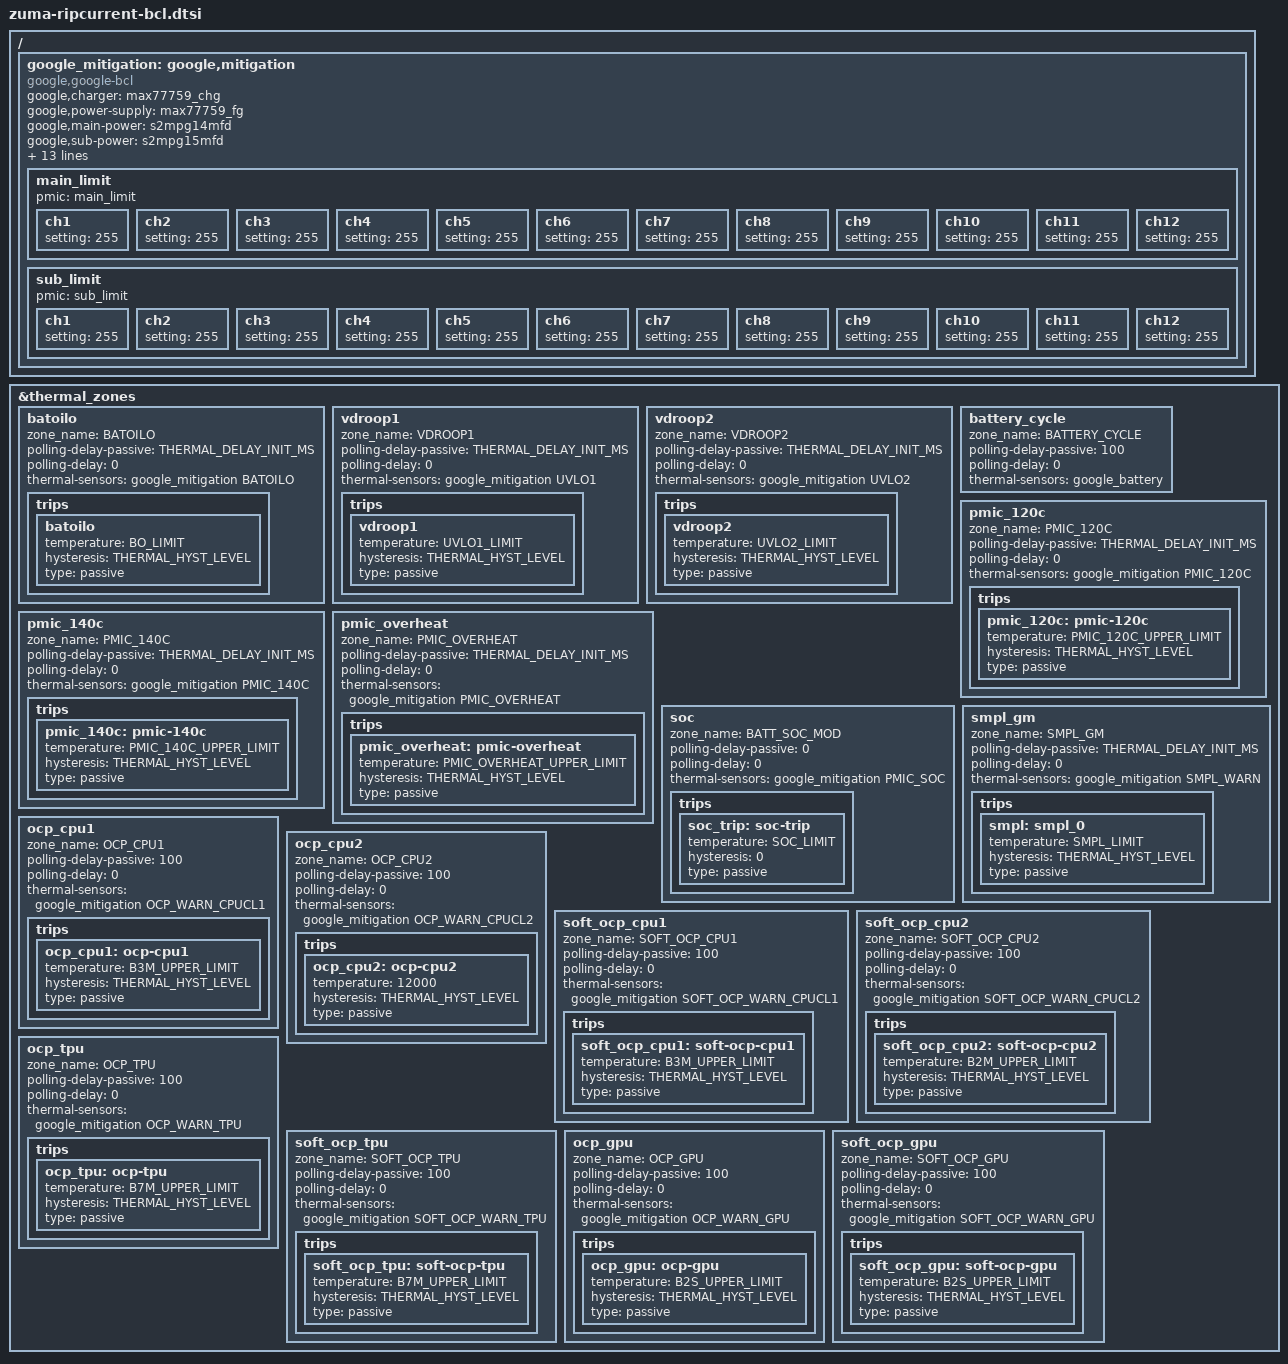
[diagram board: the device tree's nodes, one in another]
// SPDX-License-Identifier: GPL-2.0
/*
 * Google Zuma Ripcurrent-specific bcl device tree source
 *
 * Copyright (c) 2022 Google, LLC
 *		https://www.google.com
 */

#include <dt-bindings/thermal/thermal.h>
#include <dt-bindings/soc/google/zuma-bcl.h>

/ {
	fragment@battery {
		target-path = "/";
		__overlay__ {
			google_mitigation: google,mitigation {
				compatible = "google,google-bcl";
				#thermal-sensor-cells = <1>;
				google,charger = <&max77759_chg>;
				google,power-supply = <&max77759_fg>;
				google,main-power = <&s2mpg14mfd>;
				google,sub-power = <&s2mpg15mfd>;
				ppm_settings = <0>;
				mpmm_settings = <0x1a>;
				tpu_con_heavy = <0xfff041c3>;
				tpu_con_light = <0xfff041c1>;
				tpu_clkdivstep = <0x1>;
				gpu_con_heavy = <0xfff04385>;
				gpu_con_light = <0xfff041c1>;
				gpu_clkdivstep = <0x1>;
				cpu2_clkdivstep = <0x1>;
				cpu1_clkdivstep = <0x1>;
				cpu0_clkdivstep = <0x1>;
				odpm_ratio = <3>;
				gpios = <&gpa9 5 0>,		/* VDROOP1 */
					<&gpa9 6 0>,		/* VDROOP2 */
					<&gpp19 2 0>,		/* MODEM 1 */
					<&gpp10 0 0>;		/* MODEM 2 */

				main_limit {
					pmic = "main_limit";
					ch1 {
						/* BUCK1M Min: 0.006868132 mW Max: 14403.51 mW */
						setting = <255>;   /* BUCK1M LSB: 0.006868132 mW */
					};
					ch2 {
						/* BUCK2M Min: 0.013736264 mW Max: 28807.01 mW */
						setting = <255>;   /* BUCK2M LSB: 0.013736264 mW */
					};
					ch3 {
						/* BUCK3M Min: 0.020604396 mW Max: 43210.53 mW */
						setting = <255>;   /* BUCK3M LSB: 0.020604396 mW */
					};
					ch4 {
						/* BUCK4M Min: 0.013736264 mW Max: 28807.01 mW */
						setting = <255>;   /* BUCK4M LSB: 0.013736264 mW */
					};
					ch5 {
						/* BUCK5M Min: 0.020604396 mW Max: 43210.53 mW */
						setting = <255>;   /* BUCK5M LSB: 0.020604396 mW */
					};
					ch6 {
						/* BUCK6M Min: 0.006868132 mW Max: 14403.51 mW */
						setting = <255>;   /* BUCK6M LSB: 0.006868132 mW */
					};
					ch7 {
						/* BUCK7M Min: 0.020604396 mW Max: 43210.53 mW */
						setting = <255>;   /* BUCK7M LSB: 0.020604396 mW */
					};
					ch8 {
						/* BUCK8M Min: 0.006868132 mW Max: 14403.51 mW */
						setting = <255>;   /* BUCK8M LSB: 0.006868132 mW */
					};
					ch9 {
						setting = <255>;   /* LDO15M LSB: 0.001831502 mW */
					};
					ch10 {
						setting = <255>;   /* VSEN_C1 LSB: 0.0021978021 V */
					};
					ch11 {
						setting = <255>;  /* VSEN_C2 LSB: 0.0021978021 V */
					};
					ch12 {
						setting = <255>;  /* VSEN_C3 LSB: 0.0021978021 V */
					};
				};
				sub_limit {
					pmic = "sub_limit";
					ch1 {
						/* BUCK1S Min: 0.013736264 mW Max: 28807.01 mW */
						setting = <255>;   /* BUCK1S LSB: 0.013736264 mW */
					};
					ch2 {
						/* BUCK2S Min: 0.013736264 mW Max: 28807.01 mW */
						setting = <255>;   /* BUCK2S LSB: 0.013736264 mW */
					};
					ch3 {
						/* BUCK4S Min: 0.006868132 mW Max: 14403.51 mW */
						setting = <255>;   /* BUCK4S LSB: 0.006868132 mW */
					};
					ch4 {
						/* BUCK5S Min: 0.006868132 mW Max: 14403.51 mW */
						setting = <255>;   /* BUCK5S LSB: 0.006868132 mW */
					};
					ch5 {
						/* BUCK8S Min: 0.006868132 mW Max: 14403.51 mW */
						setting = <255>;   /* BUCK8S LSB: 0.006868132 mW */
					};
					ch6 {
						/* BUCK9S Min: 0.006868132 mW Max: 14403.51 mW */
						setting = <255>;   /* BUCK9S LSB: 0.006868132 mW */
					};
					ch7 {
						setting = <255>;   /* LDO2S LSB: 0.001831502 mW */
					};
					ch8 {
						setting = <255>;   /* LDO9S LSB: 0.000457875 mW */
					};
					ch9 {
						setting = <255>;   /* LDO29S LSB: 0.000915751 mW */
					};
					ch10 {
						setting = <255>;  /* VSEN_C4 LSB: 0.0021978021 V */
					};
					ch11 {
						setting = <255>;  /* VSEN_C5 LSB: 0.0021978021 V */
					};
					ch12 {
						setting = <255>;  /* VSEN_C6 LSB: 0.0021978021 V */
					};
				};
			};
		};
	};
};

/* Thermal Zones */
&thermal_zones {
	batoilo {
		zone_name  = "BATOILO";
		polling-delay-passive = <THERMAL_DELAY_INIT_MS>;
		polling-delay = <0>;
		thermal-sensors = <&google_mitigation BATOILO>;
		trips {
			batoilo: batoilo{
				temperature = <BO_LIMIT>;
				hysteresis = <THERMAL_HYST_LEVEL>;
				type = "passive";
			};
		};
	};

	vdroop1 {
		zone_name  = "VDROOP1";
		polling-delay-passive = <THERMAL_DELAY_INIT_MS>;
		polling-delay = <0>;
		thermal-sensors = <&google_mitigation UVLO1>;
		trips {
			vdroop1: vdroop1{
				temperature = <UVLO1_LIMIT>;
				hysteresis = <THERMAL_HYST_LEVEL>;
				type = "passive";
			};
		};
	};

	vdroop2 {
		zone_name  = "VDROOP2";
		polling-delay-passive = <THERMAL_DELAY_INIT_MS>;
		polling-delay = <0>;
		thermal-sensors = <&google_mitigation UVLO2>;
		trips {
			vdroop2: vdroop2{
				temperature = <UVLO2_LIMIT>;
				hysteresis = <THERMAL_HYST_LEVEL>;
				type = "passive";
			};
		};
	};

	battery_cycle {
		zone_name  = "BATTERY_CYCLE";
		polling-delay-passive = <100>;
		polling-delay = <0>;
		thermal-sensors = <&google_battery>;
	};

	pmic_120c {
		zone_name  = "PMIC_120C";
		polling-delay-passive = <THERMAL_DELAY_INIT_MS>;
		polling-delay = <0>;
		thermal-sensors = <&google_mitigation PMIC_120C>;
		trips {
			pmic_120c: pmic-120c {
				temperature = <PMIC_120C_UPPER_LIMIT>;
				hysteresis = <THERMAL_HYST_LEVEL>;
				type = "passive";
			};
		};
	};

	pmic_140c {
		zone_name  = "PMIC_140C";
		polling-delay-passive = <THERMAL_DELAY_INIT_MS>;
		polling-delay = <0>;
		thermal-sensors = <&google_mitigation PMIC_140C>;
		trips {
			pmic_140c: pmic-140c {
				temperature = <PMIC_140C_UPPER_LIMIT>;
				hysteresis = <THERMAL_HYST_LEVEL>;
				type = "passive";
			};
		};
	};

	pmic_overheat {
		zone_name  = "PMIC_OVERHEAT";
		polling-delay-passive = <THERMAL_DELAY_INIT_MS>;
		polling-delay = <0>;
		thermal-sensors = <&google_mitigation PMIC_OVERHEAT>;
		trips {
			pmic_overheat: pmic-overheat{
				temperature = <PMIC_OVERHEAT_UPPER_LIMIT>;
				hysteresis = <THERMAL_HYST_LEVEL>;
				type = "passive";
			};
		};
	};

	soc {
		zone_name  = "BATT_SOC_MOD";
		polling-delay-passive = <0>;
		polling-delay = <0>;
		thermal-sensors = <&google_mitigation PMIC_SOC>;

		trips {
			soc_trip:soc-trip {
				temperature = <SOC_LIMIT>;
				hysteresis = <0>;
				type = "passive";
			};
		};
	};

	smpl_gm {
		zone_name  = "SMPL_GM";
		polling-delay-passive = <THERMAL_DELAY_INIT_MS>;
		polling-delay = <0>;
		thermal-sensors = <&google_mitigation SMPL_WARN>;

		trips {
			smpl:smpl_0 {
				temperature = <SMPL_LIMIT>;
				hysteresis = <THERMAL_HYST_LEVEL>;
				type = "passive";
			};
		};
	};
	ocp_cpu1 {
		zone_name  = "OCP_CPU1";
		polling-delay-passive = <100>;
		polling-delay = <0>;
		thermal-sensors = <&google_mitigation OCP_WARN_CPUCL1>;

		trips {
			ocp_cpu1:ocp-cpu1 {
				temperature = <B3M_UPPER_LIMIT>;
				hysteresis = <THERMAL_HYST_LEVEL>;
				type = "passive";
			};
		};
	};
	ocp_cpu2 {
		zone_name  = "OCP_CPU2";
		polling-delay-passive = <100>;
		polling-delay = <0>;
		thermal-sensors = <&google_mitigation OCP_WARN_CPUCL2>;

		trips {
			ocp_cpu2:ocp-cpu2 {
				temperature = <12000>;
				hysteresis = <THERMAL_HYST_LEVEL>;
				type = "passive";
			};
		};
	};
	soft_ocp_cpu1 {
		zone_name  = "SOFT_OCP_CPU1";
		polling-delay-passive = <100>;
		polling-delay = <0>;
		thermal-sensors = <&google_mitigation SOFT_OCP_WARN_CPUCL1>;

		trips {
			soft_ocp_cpu1:soft-ocp-cpu1 {
				temperature = <B3M_UPPER_LIMIT>;
				hysteresis = <THERMAL_HYST_LEVEL>;
				type = "passive";
			};
		};
	};
	soft_ocp_cpu2 {
		zone_name  = "SOFT_OCP_CPU2";
		polling-delay-passive = <100>;
		polling-delay = <0>;
		thermal-sensors = <&google_mitigation SOFT_OCP_WARN_CPUCL2>;

		trips {
			soft_ocp_cpu2:soft-ocp-cpu2 {
				temperature = <B2M_UPPER_LIMIT>;
				hysteresis = <THERMAL_HYST_LEVEL>;
				type = "passive";
			};
		};
	};
	ocp_tpu {
		zone_name  = "OCP_TPU";
		polling-delay-passive = <100>;
		polling-delay = <0>;
		thermal-sensors = <&google_mitigation OCP_WARN_TPU>;

		trips {
			ocp_tpu:ocp-tpu{
				temperature = <B7M_UPPER_LIMIT>;
				hysteresis = <THERMAL_HYST_LEVEL>;
				type = "passive";
			};
		};
	};
	soft_ocp_tpu {
		zone_name  = "SOFT_OCP_TPU";
		polling-delay-passive = <100>;
		polling-delay = <0>;
		thermal-sensors = <&google_mitigation SOFT_OCP_WARN_TPU>;

		trips {
			soft_ocp_tpu:soft-ocp-tpu {
				temperature = <B7M_UPPER_LIMIT>;
				hysteresis = <THERMAL_HYST_LEVEL>;
				type = "passive";
			};
		};
	};
	ocp_gpu {
		zone_name  = "OCP_GPU";
		polling-delay-passive = <100>;
		polling-delay = <0>;
		thermal-sensors = <&google_mitigation OCP_WARN_GPU>;

		trips {
			ocp_gpu:ocp-gpu{
				temperature = <B2S_UPPER_LIMIT>;
				hysteresis = <THERMAL_HYST_LEVEL>;
				type = "passive";
			};
		};
	};
	soft_ocp_gpu {
		zone_name  = "SOFT_OCP_GPU";
		polling-delay-passive = <100>;
		polling-delay = <0>;
		thermal-sensors = <&google_mitigation SOFT_OCP_WARN_GPU>;

		trips {
			soft_ocp_gpu:soft-ocp-gpu {
				temperature = <B2S_UPPER_LIMIT>;
				hysteresis = <THERMAL_HYST_LEVEL>;
				type = "passive";
			};
		};
	};
};
